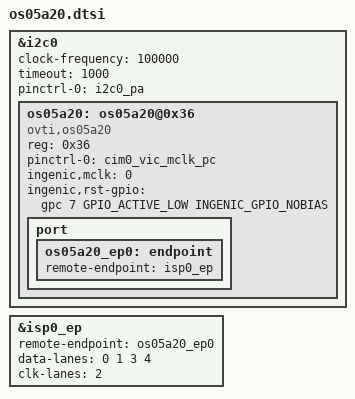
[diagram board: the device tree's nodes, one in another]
&i2c0 {
	status = "okay";
	clock-frequency = <100000>;
	timeout = <1000>;
	pinctrl-names = "default";
	pinctrl-0 = <&i2c0_pa>;

	os05a20:os05a20@0x36 {
		status = "ok";
		compatible = "ovti,os05a20";
		reg = <0x36>;
		pinctrl-names = "default";
		pinctrl-0 = <&cim0_vic_mclk_pc>;

		ingenic,mclk = <0>;
		ingenic,rst-gpio = <&gpc 7 GPIO_ACTIVE_LOW INGENIC_GPIO_NOBIAS>;
	/*	ingenic,ircutp-gpio = <&gpa 17 GPIO_ACTIVE_HIGH INGENIC_GPIO_NOBIAS>;
		ingenic,ircutn-gpio = <&gpa 18 GPIO_ACTIVE_LOW INGENIC_GPIO_NOBIAS>;
	*/
		port {
			os05a20_ep0:endpoint {
				remote-endpoint = <&isp0_ep>;
			};
		};
	};

};


&isp0_ep {
	remote-endpoint = <&os05a20_ep0>;
	data-lanes = <0 1 3 4>;
	clk-lanes = <2>;
/*	data-lanes = <0 1>;
	clk-lanes = <2>;
*/
};

